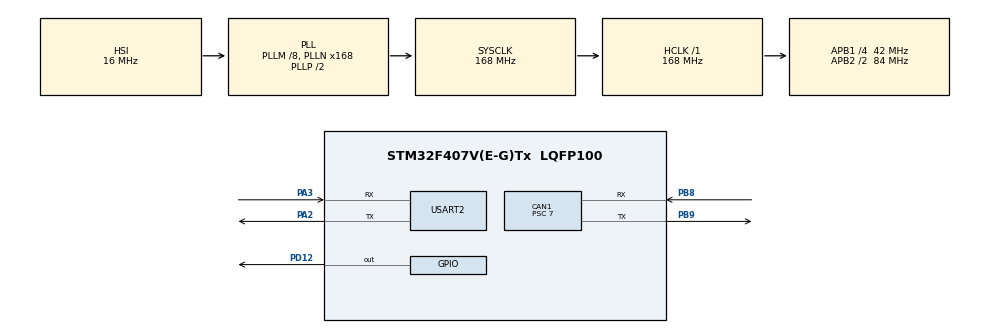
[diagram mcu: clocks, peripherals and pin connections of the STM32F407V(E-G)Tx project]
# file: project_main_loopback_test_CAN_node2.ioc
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CAN1.BS1=CAN_BS1_8TQ
CAN1.BS2=CAN_BS2_3TQ
CAN1.CalculateBaudRate=499999
CAN1.CalculateTimeBit=2000
CAN1.CalculateTimeQuantum=166.66666666666669
CAN1.Prescaler=7
Mcu.Family=STM32F4
Mcu.Name=STM32F407V(E-G)Tx
Mcu.Package=LQFP100
NVIC.CAN1_RX0_IRQn=true\:0\:0\:false\:false\:true\:true\:true\:true
NVIC.PriorityGroup=NVIC_PRIORITYGROUP_0
PA2.Mode=Asynchronous
PA2.Signal=USART2_TX
PA3.Mode=Asynchronous
PA3.Signal=USART2_RX
PB8.Mode=CAN_Activate
PB8.Signal=CAN1_RX
PB9.Mode=CAN_Activate
PB9.Signal=CAN1_TX
PD12.Signal=GPIO_Output
ProjectManager.HeapSize=0x200
ProjectManager.StackSize=0x400
ProjectManager.TargetToolchain=STM32CubeIDE
RCC.48MHZClocksFreq_Value=48000000
RCC.AHBFreq_Value=168000000
RCC.APB1CLKDivider=RCC_HCLK_DIV4
RCC.APB1Freq_Value=42000000
RCC.APB1TimFreq_Value=84000000
RCC.APB2CLKDivider=RCC_HCLK_DIV2
RCC.APB2Freq_Value=84000000
RCC.APB2TimFreq_Value=168000000
RCC.CortexFreq_Value=168000000
RCC.HCLKFreq_Value=168000000
RCC.HSE_VALUE=8000000
RCC.HSI_VALUE=16000000
RCC.LSE_VALUE=32768
RCC.PLLM=8
RCC.PLLN=168
RCC.PLLQ=7
RCC.SYSCLKFreq_VALUE=168000000
RCC.SYSCLKSource=RCC_SYSCLKSOURCE_PLLCLK
RCC.VCOOutputFreq_Value=336000000
USART2.VirtualMode=VM_ASYNC
board=STM32F407G-DISC1

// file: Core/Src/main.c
/* USER CODE BEGIN Header */
/**
  ******************************************************************************
  * @file           : main.c
  * @brief          : Main program body
  ******************************************************************************
  * @attention
  *
  * Copyright (c) 2026 STMicroelectronics.
  * All rights reserved.
  *
  * This software is licensed under terms that can be found in the LICENSE file
  * in the root directory of this software component.
  * If no LICENSE file comes with this software, it is provided AS-IS.
  *
  ******************************************************************************
  */
/* USER CODE END Header */
#include "main.h"

/* USER CODE BEGIN Includes */
#include "can.h"
#include <string.h>
#include <stdio.h>
/* USER CODE END Includes */

CAN_HandleTypeDef hcan1;

UART_HandleTypeDef huart2;

/* USER CODE BEGIN PV */
char buf[100];
/* USER CODE END PV */

void SystemClock_Config(void);
static void MX_GPIO_Init(void);
static void MX_CAN1_Init(void);
static void MX_USART2_UART_Init(void);

int main(void)
{

  /* MCU Configuration--------------------------------------------------------*/

  /* Reset of all peripherals, Initializes the Flash interface and the Systick. */
  HAL_Init();

  /* Configure the system clock */
  SystemClock_Config();

  /* Initialize all configured peripherals */
  MX_GPIO_Init();
  MX_CAN1_Init();
  MX_USART2_UART_Init();
  /* USER CODE BEGIN 2 */
  MX_CAN1_Filter_Config();
  /* USER CODE END 2 */

  /* Infinite loop */
  while (1)
  {

    /* USER CODE BEGIN 3 */

  CAN_SensorFrame_t frame;

  if (CAN_N2_GetFrame(&frame) == HAL_OK)
  {
	  HAL_GPIO_WritePin(GPIOD, GPIO_PIN_12, GPIO_PIN_SET);   // LED ON
//	  sprintf(buf,
//              "RX OK | Status=%d Temp=%d MQ2=%d Mag=%d\r\n",
//              frame.status,
//              frame.temperature,
//              frame.mq2,
//              frame.magnitude);
  }
  else
  {
	   HAL_GPIO_WritePin(GPIOD, GPIO_PIN_12, GPIO_PIN_RESET); // LED OFF
	  //sprintf(buf, "Waiting for CAN...\r\n");
  }

  HAL_UART_Transmit(&huart2,(uint8_t*)buf, strlen(buf),100);

  HAL_Delay(500);

  /* USER CODE END 3 */
 }
}
void SystemClock_Config(void)
{
  RCC_OscInitTypeDef RCC_OscInitStruct = {0};
  RCC_ClkInitTypeDef RCC_ClkInitStruct = {0};

  /** Configure the main internal regulator output voltage
  */
  __HAL_RCC_PWR_CLK_ENABLE();
  __HAL_PWR_VOLTAGESCALING_CONFIG(PWR_REGULATOR_VOLTAGE_SCALE1);

  /** Initializes the RCC Oscillators according to the specified parameters
  * in the RCC_OscInitTypeDef structure.
  */
  RCC_OscInitStruct.OscillatorType = RCC_OSCILLATORTYPE_HSI;
  RCC_OscInitStruct.HSIState = RCC_HSI_ON;
  RCC_OscInitStruct.HSICalibrationValue = RCC_HSICALIBRATION_DEFAULT;
  RCC_OscInitStruct.PLL.PLLState = RCC_PLL_ON;
  RCC_OscInitStruct.PLL.PLLSource = RCC_PLLSOURCE_HSI;
  RCC_OscInitStruct.PLL.PLLM = 8;
  RCC_OscInitStruct.PLL.PLLN = 168;
  RCC_OscInitStruct.PLL.PLLP = RCC_PLLP_DIV2;
  RCC_OscInitStruct.PLL.PLLQ = 7;
  if (HAL_RCC_OscConfig(&RCC_OscInitStruct) != HAL_OK)
  {
    Error_Handler();
  }

  /** Initializes the CPU, AHB and APB buses clocks
  */
  RCC_ClkInitStruct.ClockType = RCC_CLOCKTYPE_HCLK|RCC_CLOCKTYPE_SYSCLK
                              |RCC_CLOCKTYPE_PCLK1|RCC_CLOCKTYPE_PCLK2;
  RCC_ClkInitStruct.SYSCLKSource = RCC_SYSCLKSOURCE_PLLCLK;
  RCC_ClkInitStruct.AHBCLKDivider = RCC_SYSCLK_DIV1;
  RCC_ClkInitStruct.APB1CLKDivider = RCC_HCLK_DIV4;
  RCC_ClkInitStruct.APB2CLKDivider = RCC_HCLK_DIV2;

  if (HAL_RCC_ClockConfig(&RCC_ClkInitStruct, FLASH_LATENCY_5) != HAL_OK)
  {
    Error_Handler();
  }
}

static void MX_CAN1_Init(void)
{

  hcan1.Instance = CAN1;
  hcan1.Init.Prescaler = 7;
  hcan1.Init.Mode = CAN_MODE_NORMAL;
  hcan1.Init.SyncJumpWidth = CAN_SJW_1TQ;
  hcan1.Init.TimeSeg1 = CAN_BS1_8TQ;
  hcan1.Init.TimeSeg2 = CAN_BS2_3TQ;
  hcan1.Init.TimeTriggeredMode = DISABLE;
  hcan1.Init.AutoBusOff = DISABLE;
  hcan1.Init.AutoWakeUp = DISABLE;
  hcan1.Init.AutoRetransmission = DISABLE;
  hcan1.Init.ReceiveFifoLocked = DISABLE;
  hcan1.Init.TransmitFifoPriority = DISABLE;
  if (HAL_CAN_Init(&hcan1) != HAL_OK)
  {
    Error_Handler();
  }

}

static void MX_USART2_UART_Init(void)
{

  huart2.Instance = USART2;
  huart2.Init.BaudRate = 115200;
  huart2.Init.WordLength = UART_WORDLENGTH_8B;
  huart2.Init.StopBits = UART_STOPBITS_1;
  huart2.Init.Parity = UART_PARITY_NONE;
  huart2.Init.Mode = UART_MODE_TX_RX;
  huart2.Init.HwFlowCtl = UART_HWCONTROL_NONE;
  huart2.Init.OverSampling = UART_OVERSAMPLING_16;
  if (HAL_UART_Init(&huart2) != HAL_OK)
  {
    Error_Handler();
  }

}

static void MX_GPIO_Init(void)
{
  GPIO_InitTypeDef GPIO_InitStruct = {0};

  /* GPIO Ports Clock Enable */
  __HAL_RCC_GPIOA_CLK_ENABLE();
  __HAL_RCC_GPIOD_CLK_ENABLE();
  __HAL_RCC_GPIOB_CLK_ENABLE();

  /*Configure GPIO pin Output Level */
  HAL_GPIO_WritePin(GPIOD, GPIO_PIN_12, GPIO_PIN_RESET);

  /*Configure GPIO pin : PD12 */
  GPIO_InitStruct.Pin = GPIO_PIN_12;
  GPIO_InitStruct.Mode = GPIO_MODE_OUTPUT_PP;
  GPIO_InitStruct.Pull = GPIO_NOPULL;
  GPIO_InitStruct.Speed = GPIO_SPEED_FREQ_LOW;
  HAL_GPIO_Init(GPIOD, &GPIO_InitStruct);

}

void Error_Handler(void)
{
  __disable_irq();
  while (1)
  {
  }
}
